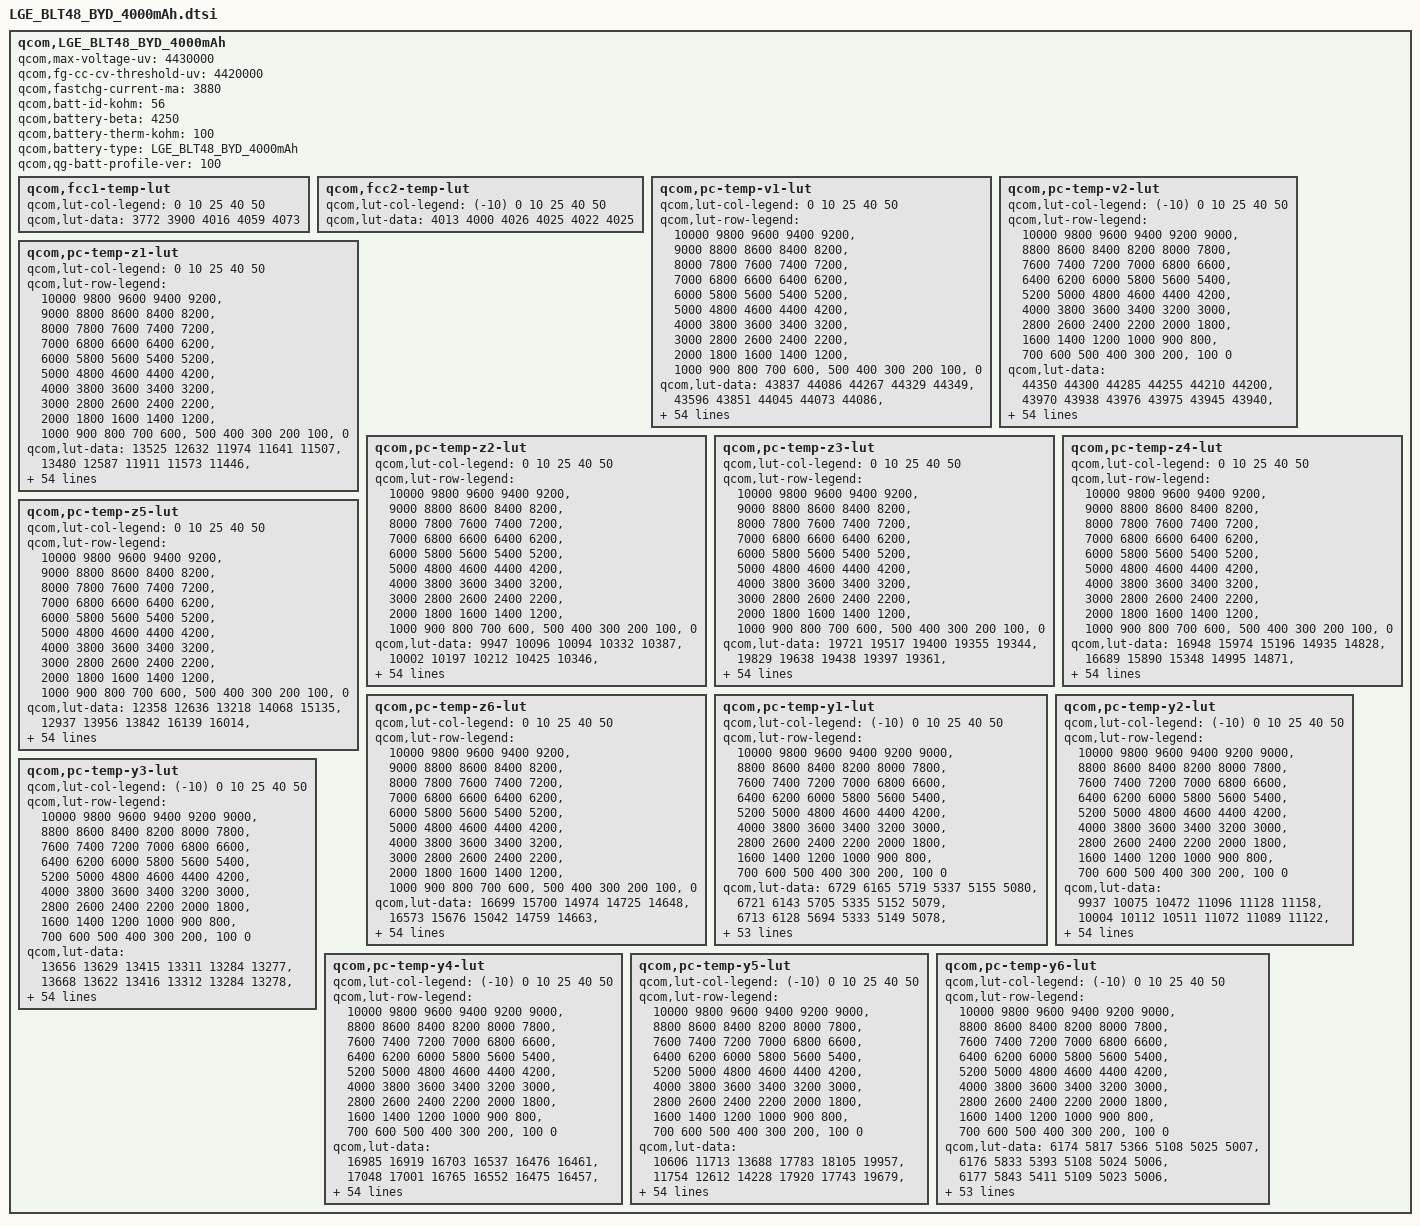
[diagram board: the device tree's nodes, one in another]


qcom,LGE_BLT48_BYD_4000mAh {
    /* 4895688_LGE_BYD_4500mAh_averaged_MasterSlave_Nov20th2020 */
    qcom,max-voltage-uv = <4430000>;
    qcom,fg-cc-cv-threshold-uv = <4420000>;
    qcom,fastchg-current-ma = <3880>;
    qcom,batt-id-kohm = <56>;
    qcom,battery-beta = <4250>;
    qcom,battery-therm-kohm = <100>;
    qcom,battery-type = "LGE_BLT48_BYD_4000mAh";
    qcom,qg-batt-profile-ver = <100>;

	qcom,fcc1-temp-lut {
		qcom,lut-col-legend = <0 10 25 40 50>;
		qcom,lut-data = <3772 3900 4016 4059 4073>;
	};

	qcom,fcc2-temp-lut {
		qcom,lut-col-legend = <(-10) 0 10 25 40 50>;
		qcom,lut-data = <4013 4000 4026 4025 4022 4025>;
	};

	qcom,pc-temp-v1-lut {
		qcom,lut-col-legend = <0 10 25 40 50>;
		qcom,lut-row-legend = <10000 9800 9600 9400 9200>,
			<9000 8800 8600 8400 8200>,
			<8000 7800 7600 7400 7200>,
			<7000 6800 6600 6400 6200>,
			<6000 5800 5600 5400 5200>,
			<5000 4800 4600 4400 4200>,
			<4000 3800 3600 3400 3200>,
			<3000 2800 2600 2400 2200>,
			<2000 1800 1600 1400 1200>,
			<1000 900 800 700 600>,
			<500 400 300 200 100>,
			<0>;
		qcom,lut-data = <43837 44086 44267 44329 44349>,
			<43596 43851 44045 44073 44086>,
			<43358 43622 43817 43855 43863>,
			<43121 43400 43590 43644 43651>,
			<42886 43172 43366 43423 43433>,
			<42653 42933 43137 43199 43213>,
			<42419 42690 42899 42968 42986>,
			<42187 42450 42655 42729 42747>,
			<41960 42212 42411 42486 42503>,
			<41737 41978 42168 42242 42260>,
			<41518 41747 41928 41997 42016>,
			<41305 41521 41694 41758 41778>,
			<41097 41300 41465 41526 41544>,
			<40895 41086 41242 41297 41314>,
			<40694 40876 41025 41074 41089>,
			<40499 40670 40816 40855 40868>,
			<40310 40470 40613 40645 40658>,
			<40125 40285 40417 40443 40456>,
			<39953 40117 40231 40251 40264>,
			<39805 39955 40062 40077 40086>,
			<39673 39792 39882 39906 39914>,
			<39536 39629 39644 39698 39714>,
			<39392 39443 39376 39449 39474>,
			<39245 39183 39173 39227 39250>,
			<39094 38936 39020 39051 39068>,
			<38934 38802 38891 38899 38908>,
			<38788 38713 38779 38769 38771>,
			<38667 38642 38680 38657 38653>,
			<38561 38578 38588 38556 38547>,
			<38483 38521 38499 38460 38449>,
			<38432 38463 38421 38374 38360>,
			<38390 38404 38354 38295 38279>,
			<38352 38350 38296 38222 38203>,
			<38318 38302 38243 38158 38135>,
			<38285 38258 38196 38108 38078>,
			<38251 38219 38150 38059 38022>,
			<38216 38187 38107 38004 37956>,
			<38173 38149 38063 37945 37882>,
			<38112 38085 38001 37875 37802>,
			<38036 37991 37913 37791 37715>,
			<37938 37886 37809 37694 37618>,
			<37808 37762 37690 37581 37502>,
			<37660 37620 37550 37448 37367>,
			<37494 37452 37381 37282 37207>,
			<37380 37290 37222 37128 37058>,
			<37267 37179 37111 37026 36962>,
			<37224 37144 37079 36998 36939>,
			<37185 37123 37063 36983 36920>,
			<37152 37096 37040 36965 36903>,
			<37102 37065 37004 36926 36861>,
			<36933 36880 36809 36699 36614>,
			<36500 36450 36388 36274 36186>,
			<35928 35888 35829 35708 35620>,
			<35159 35122 35063 34937 34850>,
			<33921 33918 33878 33747 33654>,
			<30000 30000 30000 30000 30000>;
	};

	qcom,pc-temp-v2-lut {
		qcom,lut-col-legend = <(-10) 0 10 25 40 50>;
		qcom,lut-row-legend = <10000 9800 9600 9400 9200 9000>,
			<8800 8600 8400 8200 8000 7800>,
			<7600 7400 7200 7000 6800 6600>,
			<6400 6200 6000 5800 5600 5400>,
			<5200 5000 4800 4600 4400 4200>,
			<4000 3800 3600 3400 3200 3000>,
			<2800 2600 2400 2200 2000 1800>,
			<1600 1400 1200 1000 900 800>,
			<700 600 500 400 300 200>,
			<100 0>;
		qcom,lut-data = <44350 44300 44285 44255 44210 44200>,
			<43970 43938 43976 43975 43945 43940>,
			<43631 43613 43692 43713 43693 43691>,
			<43343 43330 43437 43471 43458 43457>,
			<43101 43088 43214 43252 43240 43239>,
			<42862 42848 42987 43029 43018 43017>,
			<42603 42591 42744 42790 42783 42781>,
			<42345 42333 42495 42546 42543 42541>,
			<42122 42091 42247 42305 42303 42302>,
			<41930 41866 41997 42064 42062 42063>,
			<41718 41633 41753 41826 41825 41827>,
			<41430 41359 41518 41591 41589 41592>,
			<41125 41090 41290 41360 41358 41362>,
			<40904 40914 41071 41134 41133 41136>,
			<40743 40803 40860 40915 40914 40914>,
			<40547 40665 40653 40702 40702 40701>,
			<40201 40389 40454 40494 40494 40495>,
			<39811 40040 40252 40292 40294 40295>,
			<39549 39764 40021 40106 40107 40109>,
			<39356 39535 39763 39933 39931 39932>,
			<39174 39323 39519 39738 39738 39739>,
			<38981 39125 39294 39480 39495 39502>,
			<38797 38936 39087 39215 39246 39262>,
			<38635 38727 38904 39011 39045 39062>,
			<38486 38489 38740 38839 38870 38885>,
			<38366 38311 38593 38690 38721 38734>,
			<38276 38216 38465 38562 38595 38607>,
			<38200 38147 38345 38448 38484 38496>,
			<38127 38085 38211 38343 38383 38392>,
			<38060 38031 38070 38247 38288 38294>,
			<37994 37981 37974 38158 38202 38206>,
			<37928 37932 37922 38074 38125 38127>,
			<37862 37885 37879 37997 38051 38052>,
			<37793 37834 37832 37924 37979 37980>,
			<37720 37783 37786 37855 37910 37913>,
			<37644 37728 37739 37787 37830 37829>,
			<37562 37665 37694 37723 37732 37710>,
			<37478 37597 37645 37657 37626 37584>,
			<37399 37525 37582 37584 37532 37482>,
			<37321 37450 37506 37505 37442 37389>,
			<37250 37363 37414 37415 37350 37295>,
			<37185 37249 37294 37310 37254 37200>,
			<37122 37124 37158 37188 37144 37091>,
			<37057 36997 37003 37044 37008 36956>,
			<36984 36899 36857 36900 36875 36824>,
			<36888 36818 36769 36844 36831 36787>,
			<36826 36785 36738 36824 36818 36776>,
			<36757 36745 36703 36805 36803 36762>,
			<36663 36698 36667 36775 36778 36737>,
			<36526 36603 36581 36695 36702 36649>,
			<36284 36372 36341 36441 36448 36362>,
			<35910 35944 35891 35973 35974 35880>,
			<35342 35311 35246 35337 35349 35244>,
			<34522 34392 34320 34449 34495 34375>,
			<33184 32856 32921 33002 33226 33103>,
			<29670 29562 29533 29532 29517 29517>;
	};

	qcom,pc-temp-z1-lut {
		qcom,lut-col-legend = <0 10 25 40 50>;
		qcom,lut-row-legend = <10000 9800 9600 9400 9200>,
			<9000 8800 8600 8400 8200>,
			<8000 7800 7600 7400 7200>,
			<7000 6800 6600 6400 6200>,
			<6000 5800 5600 5400 5200>,
			<5000 4800 4600 4400 4200>,
			<4000 3800 3600 3400 3200>,
			<3000 2800 2600 2400 2200>,
			<2000 1800 1600 1400 1200>,
			<1000 900 800 700 600>,
			<500 400 300 200 100>,
			<0>;
		qcom,lut-data = <13525 12632 11974 11641 11507>,
			<13480 12587 11911 11573 11446>,
			<13446 12561 11883 11549 11427>,
			<13425 12535 11865 11532 11416>,
			<13409 12515 11850 11517 11407>,
			<13394 12502 11838 11505 11400>,
			<13380 12491 11825 11498 11395>,
			<13367 12478 11811 11493 11392>,
			<13352 12463 11803 11490 11390>,
			<13333 12455 11798 11486 11388>,
			<13316 12457 11795 11483 11386>,
			<13305 12461 11794 11481 11385>,
			<13295 12462 11793 11480 11386>,
			<13291 12461 11792 11479 11386>,
			<13303 12461 11793 11479 11386>,
			<13319 12465 11794 11480 11385>,
			<13319 12472 11796 11481 11386>,
			<13300 12474 11799 11483 11387>,
			<13284 12469 11803 11486 11389>,
			<13287 12465 11809 11489 11391>,
			<13299 12472 11814 11492 11395>,
			<13310 12494 11817 11495 11397>,
			<13328 12504 11819 11497 11400>,
			<13345 12501 11823 11499 11402>,
			<13346 12497 11834 11504 11406>,
			<13336 12501 11843 11509 11411>,
			<13328 12511 11848 11515 11415>,
			<13334 12518 11852 11520 11420>,
			<13349 12522 11856 11526 11424>,
			<13362 12527 11862 11531 11428>,
			<13377 12531 11868 11536 11432>,
			<13392 12539 11871 11541 11437>,
			<13398 12547 11875 11546 11441>,
			<13399 12552 11878 11551 11446>,
			<13401 12558 11881 11555 11450>,
			<13407 12565 11885 11560 11454>,
			<13414 12575 11893 11566 11459>,
			<13424 12585 11903 11571 11463>,
			<13441 12594 11909 11577 11467>,
			<13457 12605 11913 11582 11472>,
			<13459 12609 11917 11587 11477>,
			<13453 12606 11921 11591 11481>,
			<13459 12606 11927 11597 11485>,
			<13479 12623 11938 11605 11489>,
			<13490 12632 11949 11614 11495>,
			<13472 12662 11954 11621 11499>,
			<13485 12633 11959 11619 11500>,
			<13487 12654 11966 11622 11501>,
			<13474 12639 11965 11624 11503>,
			<13500 12654 11965 11631 11508>,
			<13559 12675 11977 11637 11517>,
			<13561 12697 11992 11650 11527>,
			<13572 12719 12015 11666 11543>,
			<13603 12774 12062 11689 11566>,
			<13603 12774 12062 11689 11566>,
			<13603 12774 12062 11689 11566>;
	};

	qcom,pc-temp-z2-lut {
		qcom,lut-col-legend = <0 10 25 40 50>;
		qcom,lut-row-legend = <10000 9800 9600 9400 9200>,
			<9000 8800 8600 8400 8200>,
			<8000 7800 7600 7400 7200>,
			<7000 6800 6600 6400 6200>,
			<6000 5800 5600 5400 5200>,
			<5000 4800 4600 4400 4200>,
			<4000 3800 3600 3400 3200>,
			<3000 2800 2600 2400 2200>,
			<2000 1800 1600 1400 1200>,
			<1000 900 800 700 600>,
			<500 400 300 200 100>,
			<0>;
		qcom,lut-data = <9947 10096 10094 10332 10387>,
			<10002 10197 10212 10425 10346>,
			<10044 10199 10340 10465 10368>,
			<10072 10169 10374 10484 10404>,
			<10095 10136 10335 10464 10396>,
			<10104 10102 10295 10408 10334>,
			<10096 10071 10285 10380 10295>,
			<10079 10052 10280 10370 10269>,
			<10062 10039 10279 10365 10247>,
			<10039 10033 10282 10378 10248>,
			<10017 10043 10290 10402 10252>,
			<10000 10063 10474 10400 10257>,
			<9985 10080 10882 10332 10266>,
			<9973 10094 11009 10280 10276>,
			<9962 10108 10961 10285 10286>,
			<9954 10124 10918 10297 10296>,
			<9950 10140 10943 10303 10307>,
			<9949 10154 10999 10307 10317>,
			<9948 10167 10982 10312 10329>,
			<9952 10181 10654 10320 10346>,
			<9964 10199 10373 10332 10368>,
			<9977 10221 10397 10364 10385>,
			<9995 10233 10459 10448 10404>,
			<10016 10238 10471 10518 10414>,
			<10038 10240 10419 10561 10404>,
			<10064 10241 10377 10590 10383>,
			<10084 10242 10388 10568 10368>,
			<10096 10244 10413 10471 10338>,
			<10104 10248 10416 10411 10307>,
			<10111 10252 10393 10393 10275>,
			<10115 10256 10374 10384 10249>,
			<10120 10259 10377 10387 10250>,
			<10124 10264 10386 10399 10267>,
			<10129 10273 10401 10417 10292>,
			<10134 10285 10434 10455 10338>,
			<10141 10295 10462 10502 10394>,
			<10149 10302 10473 10550 10446>,
			<10159 10311 10483 10602 10500>,
			<10175 10327 10495 10630 10533>,
			<10191 10347 10522 10649 10561>,
			<10201 10354 10539 10660 10579>,
			<10208 10351 10534 10645 10556>,
			<10217 10349 10524 10623 10519>,
			<10225 10353 10511 10645 10520>,
			<9633 10430 10519 10620 10517>,
			<9690 10461 10534 10514 10518>,
			<9724 10449 10519 10519 10519>,
			<9704 10453 10509 10536 10510>,
			<9695 10455 10490 10515 10526>,
			<9706 10494 10508 10589 10613>,
			<9680 10482 10553 10528 10431>,
			<9574 10435 10493 10428 10341>,
			<9492 10341 10471 10405 10304>,
			<9367 10169 10443 10336 10263>,
			<9367 10169 10443 10336 10263>,
			<9367 10169 10443 10336 10263>;
	};

	qcom,pc-temp-z3-lut {
		qcom,lut-col-legend = <0 10 25 40 50>;
		qcom,lut-row-legend = <10000 9800 9600 9400 9200>,
			<9000 8800 8600 8400 8200>,
			<8000 7800 7600 7400 7200>,
			<7000 6800 6600 6400 6200>,
			<6000 5800 5600 5400 5200>,
			<5000 4800 4600 4400 4200>,
			<4000 3800 3600 3400 3200>,
			<3000 2800 2600 2400 2200>,
			<2000 1800 1600 1400 1200>,
			<1000 900 800 700 600>,
			<500 400 300 200 100>,
			<0>;
		qcom,lut-data = <19721 19517 19400 19355 19344>,
			<19829 19638 19438 19397 19361>,
			<19892 19678 19491 19408 19375>,
			<19891 19697 19513 19414 19382>,
			<19872 19705 19519 19419 19383>,
			<19852 19709 19521 19423 19381>,
			<19832 19711 19517 19423 19380>,
			<19815 19709 19505 19411 19378>,
			<19812 19699 19494 19400 19375>,
			<19815 19685 19482 19398 19374>,
			<19818 19667 19475 19398 19373>,
			<19819 19647 19483 19395 19370>,
			<19820 19635 19501 19383 19364>,
			<19821 19627 19507 19373 19359>,
			<19828 19621 19496 19371 19357>,
			<19836 19617 19483 19370 19356>,
			<19836 19613 19478 19369 19354>,
			<19823 19608 19475 19369 19348>,
			<19805 19594 19469 19368 19342>,
			<19787 19582 19452 19365 19340>,
			<19768 19583 19439 19363 19338>,
			<19760 19588 19451 19364 19339>,
			<19768 19594 19475 19372 19344>,
			<19779 19606 19480 19380 19351>,
			<19788 19617 19460 19390 19362>,
			<19798 19617 19443 19399 19374>,
			<19805 19609 19453 19404 19380>,
			<19804 19604 19475 19407 19383>,
			<19802 19602 19486 19409 19385>,
			<19798 19601 19491 19405 19379>,
			<19790 19602 19493 19401 19369>,
			<19778 19608 19489 19398 19364>,
			<19768 19612 19479 19395 19361>,
			<19759 19610 19473 19392 19357>,
			<19750 19606 19468 19386 19352>,
			<19744 19601 19464 19381 19347>,
			<19739 19595 19461 19378 19347>,
			<19733 19589 19459 19377 19347>,
			<19725 19584 19456 19376 19347>,
			<19716 19579 19452 19376 19348>,
			<19706 19575 19449 19375 19349>,
			<19694 19571 19447 19372 19351>,
			<19682 19565 19445 19368 19352>,
			<19666 19554 19440 19370 19350>,
			<19301 19519 19425 19366 19346>,
			<19267 19502 19416 19355 19341>,
			<19266 19502 19418 19355 19333>,
			<19266 19483 19408 19347 19333>,
			<19266 19479 19407 19345 19329>,
			<19266 19415 19404 19341 19321>,
			<19266 19477 19399 19350 19344>,
			<19268 19472 19403 19360 19352>,
			<19270 19414 19374 19359 19350>,
			<19276 19340 19363 19365 19347>,
			<19276 19340 19363 19365 19347>,
			<19276 19340 19363 19365 19347>;
	};

	qcom,pc-temp-z4-lut {
		qcom,lut-col-legend = <0 10 25 40 50>;
		qcom,lut-row-legend = <10000 9800 9600 9400 9200>,
			<9000 8800 8600 8400 8200>,
			<8000 7800 7600 7400 7200>,
			<7000 6800 6600 6400 6200>,
			<6000 5800 5600 5400 5200>,
			<5000 4800 4600 4400 4200>,
			<4000 3800 3600 3400 3200>,
			<3000 2800 2600 2400 2200>,
			<2000 1800 1600 1400 1200>,
			<1000 900 800 700 600>,
			<500 400 300 200 100>,
			<0>;
		qcom,lut-data = <16948 15974 15196 14935 14828>,
			<16689 15890 15348 14995 14871>,
			<16444 15739 15210 14948 14854>,
			<16209 15513 15096 14884 14823>,
			<15982 15328 15011 14843 14797>,
			<15792 15205 14941 14808 14771>,
			<15647 15105 14888 14787 14756>,
			<15524 15027 14844 14775 14748>,
			<15413 14961 14820 14765 14743>,
			<15313 14915 14810 14753 14735>,
			<15225 14886 14800 14741 14727>,
			<15149 14865 14768 14736 14720>,
			<15081 14848 14720 14734 14715>,
			<15026 14833 14704 14732 14710>,
			<14973 14823 14703 14725 14703>,
			<14934 14819 14702 14715 14694>,
			<14924 14817 14699 14707 14688>,
			<14924 14813 14695 14699 14685>,
			<14924 14804 14695 14693 14681>,
			<14916 14796 14707 14688 14676>,
			<14897 14793 14727 14684 14670>,
			<14882 14792 14774 14699 14678>,
			<14872 14797 14848 14772 14739>,
			<14864 14892 14891 14813 14782>,
			<14868 15003 14917 14810 14778>,
			<14897 15013 14931 14803 14768>,
			<14930 14998 14909 14791 14756>,
			<14953 14979 14860 14768 14737>,
			<14973 14952 14831 14750 14723>,
			<14980 14921 14812 14739 14717>,
			<14969 14899 14803 14731 14712>,
			<14952 14880 14802 14726 14706>,
			<14937 14868 14801 14722 14700>,
			<14923 14863 14802 14721 14697>,
			<14909 14859 14804 14722 14695>,
			<14895 14855 14806 14723 14694>,
			<14883 14849 14809 14730 14700>,
			<14871 14846 14812 14744 14717>,
			<14861 14847 14813 14748 14723>,
			<14852 14849 14813 14748 14722>,
			<14847 14850 14813 14748 14720>,
			<14842 14833 14799 14741 14713>,
			<14831 14814 14777 14727 14704>,
			<14813 14799 14766 14721 14706>,
			<15068 14760 14741 14711 14700>,
			<15088 14736 14715 14698 14686>,
			<15078 14728 14702 14688 14681>,
			<15074 14729 14691 14675 14663>,
			<15067 14723 14678 14657 14646>,
			<15056 14781 14675 14657 14647>,
			<15059 14722 14697 14671 14652>,
			<15092 14748 14698 14664 14648>,
			<15108 14817 14726 14664 14649>,
			<15134 14906 14735 14656 14652>,
			<15134 14906 14735 14656 14652>,
			<15134 14906 14735 14656 14652>;
	};

	qcom,pc-temp-z5-lut {
		qcom,lut-col-legend = <0 10 25 40 50>;
		qcom,lut-row-legend = <10000 9800 9600 9400 9200>,
			<9000 8800 8600 8400 8200>,
			<8000 7800 7600 7400 7200>,
			<7000 6800 6600 6400 6200>,
			<6000 5800 5600 5400 5200>,
			<5000 4800 4600 4400 4200>,
			<4000 3800 3600 3400 3200>,
			<3000 2800 2600 2400 2200>,
			<2000 1800 1600 1400 1200>,
			<1000 900 800 700 600>,
			<500 400 300 200 100>,
			<0>;
		qcom,lut-data = <12358 12636 13218 14068 15135>,
			<12937 13956 13842 16139 16014>,
			<13374 14674 15550 17009 17224>,
			<13617 15123 16692 17611 18077>,
			<13775 15600 17267 18277 18524>,
			<13931 16212 17739 18892 18836>,
			<14097 16883 18318 19012 18976>,
			<14274 17571 18897 18649 19090>,
			<14521 18309 19057 18348 19257>,
			<14892 18923 18966 18685 19567>,
			<15342 19319 18882 19380 20054>,
			<15816 19653 20554 19439 20198>,
			<16361 20090 24403 18412 19725>,
			<17088 20666 25563 17619 19272>,
			<18661 21341 24590 17851 19668>,
			<20322 22308 23728 18429 20623>,
			<20641 23380 23944 19016 20838>,
			<20336 23610 24485 19710 20135>,
			<20063 22645 24578 20358 19580>,
			<19997 21716 23829 21023 20057>,
			<19906 22897 23188 21652 20951>,
			<20005 26842 27026 21925 21053>,
			<22469 30485 35019 22107 20220>,
			<26568 33856 36243 22081 19236>,
			<30306 36317 26891 20284 18263>,
			<34749 35305 19214 18007 17412>,
			<37489 30313 19482 17923 17627>,
			<37366 26784 20630 18837 19236>,
			<36746 25726 22220 19871 20181>,
			<35964 25092 25188 20832 20180>,
			<34152 25333 27730 21969 20166>,
			<31943 27355 28774 23704 20522>,
			<30492 29517 29498 26069 21843>,
			<29281 31058 30204 27475 22947>,
			<28665 32340 31049 28190 23718>,
			<28736 32615 31542 28567 24204>,
			<28947 32405 31374 28219 24107>,
			<29199 32117 30874 27131 23710>,
			<29643 31874 30120 26108 23373>,
			<30034 31611 28152 24887 22885>,
			<29712 31303 26838 23829 22508>,
			<28342 30932 27064 23251 22912>,
			<27731 30268 27334 22846 23628>,
			<27465 28306 26115 22810 21886>,
			<12689 28075 25125 22036 21044>,
			<11360 26977 25497 20897 20298>,
			<11307 26927 27255 21823 18947>,
			<11285 22559 25022 21274 20969>,
			<11250 22563 26929 23817 24246>,
			<11221 16310 26280 22656 21714>,
			<11236 21703 20690 19662 22908>,
			<11246 18633 19720 20729 24262>,
			<11157 14810 15436 19829 22580>,
			<11056 11897 14347 21075 20435>,
			<11056 11897 14347 21075 20435>,
			<11056 11897 14347 21075 20435>;
	};

	qcom,pc-temp-z6-lut {
		qcom,lut-col-legend = <0 10 25 40 50>;
		qcom,lut-row-legend = <10000 9800 9600 9400 9200>,
			<9000 8800 8600 8400 8200>,
			<8000 7800 7600 7400 7200>,
			<7000 6800 6600 6400 6200>,
			<6000 5800 5600 5400 5200>,
			<5000 4800 4600 4400 4200>,
			<4000 3800 3600 3400 3200>,
			<3000 2800 2600 2400 2200>,
			<2000 1800 1600 1400 1200>,
			<1000 900 800 700 600>,
			<500 400 300 200 100>,
			<0>;
		qcom,lut-data = <16699 15700 14974 14725 14648>,
			<16573 15676 15042 14759 14663>,
			<16443 15613 14994 14739 14658>,
			<16303 15490 14948 14712 14648>,
			<16152 15385 14907 14695 14637>,
			<16023 15315 14869 14681 14625>,
			<15923 15256 14837 14668 14615>,
			<15838 15204 14808 14656 14611>,
			<15767 15157 14789 14646 14607>,
			<15706 15120 14777 14639 14602>,
			<15653 15093 14767 14634 14598>,
			<15607 15072 14757 14628 14593>,
			<15566 15057 14748 14621 14587>,
			<15537 15045 14740 14615 14582>,
			<15518 15036 14733 14610 14578>,
			<15504 15032 14727 14605 14574>,
			<15494 15029 14723 14602 14570>,
			<15488 15024 14720 14598 14565>,
			<15482 15013 14719 14595 14561>,
			<15471 15005 14718 14592 14557>,
			<15456 15006 14718 14589 14554>,
			<15451 15011 14741 14596 14558>,
			<15454 15021 14791 14632 14587>,
			<15461 15071 14809 14656 14611>,
			<15471 15126 14812 14662 14617>,
			<15493 15131 14814 14665 14620>,
			<15514 15124 14810 14663 14619>,
			<15527 15115 14803 14656 14614>,
			<15539 15104 14798 14650 14608>,
			<15542 15094 14796 14644 14603>,
			<15536 15091 14793 14639 14597>,
			<15527 15091 14790 14636 14592>,
			<15520 15090 14787 14634 14588>,
			<15513 15088 14786 14632 14585>,
			<15508 15086 14786 14629 14581>,
			<15504 15084 14786 14627 14578>,
			<15502 15083 14788 14630 14581>,
			<15501 15082 14790 14635 14589>,
			<15502 15084 14791 14638 14592>,
			<15503 15090 14792 14639 14593>,
			<15504 15093 14792 14639 14593>,
			<15506 15089 14788 14635 14591>,
			<15507 15086 14781 14629 14589>,
			<15505 15084 14778 14629 14589>,
			<15457 15067 14766 14625 14586>,
			<15454 15056 14755 14614 14578>,
			<15454 15054 14751 14610 14572>,
			<15455 15048 14743 14600 14564>,
			<15456 15048 14739 14592 14555>,
			<15460 15047 14740 14591 14551>,
			<15480 15065 14751 14604 14568>,
			<15511 15085 14760 14609 14573>,
			<15542 15100 14764 14612 14576>,
			<15591 15125 14773 14617 14580>,
			<15591 15125 14773 14617 14580>,
			<15591 15125 14773 14617 14580>;
	};

	qcom,pc-temp-y1-lut {
		qcom,lut-col-legend = <(-10) 0 10 25 40 50>;
		qcom,lut-row-legend = <10000 9800 9600 9400 9200 9000>,
			<8800 8600 8400 8200 8000 7800>,
			<7600 7400 7200 7000 6800 6600>,
			<6400 6200 6000 5800 5600 5400>,
			<5200 5000 4800 4600 4400 4200>,
			<4000 3800 3600 3400 3200 3000>,
			<2800 2600 2400 2200 2000 1800>,
			<1600 1400 1200 1000 900 800>,
			<700 600 500 400 300 200>,
			<100 0>;
		qcom,lut-data = <6729 6165 5719 5337 5155 5080>,
			<6721 6143 5705 5335 5152 5079>,
			<6713 6128 5694 5333 5149 5078>,
			<6706 6118 5686 5331 5146 5076>,
			<6700 6114 5682 5328 5143 5075>,
			<6699 6114 5680 5326 5141 5073>,
			<6703 6124 5683 5324 5139 5072>,
			<6709 6138 5688 5321 5137 5070>,
			<6712 6139 5690 5321 5134 5069>,
			<6715 6132 5689 5321 5132 5068>,
			<6717 6127 5688 5322 5129 5067>,
			<6722 6131 5688 5320 5128 5067>,
			<6726 6137 5688 5317 5127 5068>,
			<6726 6140 5690 5316 5126 5067>,
			<6721 6142 5693 5315 5126 5066>,
			<6720 6144 5695 5315 5126 5066>,
			<6728 6151 5696 5316 5126 5066>,
			<6738 6158 5697 5318 5125 5067>,
			<6743 6158 5698 5321 5126 5067>,
			<6746 6153 5699 5325 5127 5068>,
			<6748 6150 5701 5328 5129 5069>,
			<6747 6153 5703 5328 5131 5070>,
			<6746 6158 5706 5328 5133 5072>,
			<6746 6159 5710 5330 5135 5074>,
			<6746 6158 5717 5334 5137 5075>,
			<6744 6157 5720 5338 5140 5077>,
			<6736 6155 5720 5342 5143 5079>,
			<6725 6153 5719 5347 5146 5081>,
			<6723 6154 5720 5351 5149 5084>,
			<6725 6161 5721 5357 5153 5086>,
			<6726 6166 5722 5361 5156 5088>,
			<6727 6162 5727 5365 5160 5091>,
			<6729 6156 5732 5368 5163 5094>,
			<6731 6156 5734 5371 5168 5097>,
			<6739 6163 5738 5375 5173 5100>,
			<6743 6166 5739 5378 5177 5102>,
			<6744 6163 5737 5384 5181 5106>,
			<6747 6159 5735 5391 5184 5109>,
			<6749 6160 5735 5395 5187 5112>,
			<6753 6164 5733 5398 5191 5115>,
			<6754 6169 5734 5402 5194 5117>,
			<6763 6180 5741 5413 5196 5119>,
			<6772 6189 5746 5417 5199 5122>,
			<6755 6183 5749 5418 5205 5125>,
			<6759 6187 5761 5426 5214 5129>,
			<6830 6199 5763 5424 5215 5133>,
			<6831 6206 5772 5433 5217 5134>,
			<6840 6210 5778 5435 5220 5134>,
			<6879 6214 5778 5433 5222 5134>,
			<6919 6230 5781 5435 5222 5135>,
			<6976 6261 5799 5444 5223 5139>,
			<7048 6282 5827 5455 5232 5146>,
			<7083 6355 5864 5476 5248 5157>,
			<7088 6389 5891 5497 5268 5173>,
			<7088 6389 5891 5497 5268 5173>,
			<7088 6389 5891 5497 5268 5173>;
	};

	qcom,pc-temp-y2-lut {
		qcom,lut-col-legend = <(-10) 0 10 25 40 50>;
		qcom,lut-row-legend = <10000 9800 9600 9400 9200 9000>,
			<8800 8600 8400 8200 8000 7800>,
			<7600 7400 7200 7000 6800 6600>,
			<6400 6200 6000 5800 5600 5400>,
			<5200 5000 4800 4600 4400 4200>,
			<4000 3800 3600 3400 3200 3000>,
			<2800 2600 2400 2200 2000 1800>,
			<1600 1400 1200 1000 900 800>,
			<700 600 500 400 300 200>,
			<100 0>;
		qcom,lut-data = <9937 10075 10472 11096 11128 11158>,
			<10004 10112 10511 11072 11089 11122>,
			<10072 10171 10571 11047 11050 11080>,
			<10135 10236 10633 11021 11013 11036>,
			<10190 10290 10682 10994 10978 10997>,
			<10229 10316 10701 10967 10948 10969>,
			<10250 10321 10695 10936 10917 10946>,
			<10268 10324 10687 10908 10891 10926>,
			<10324 10347 10689 10895 10883 10912>,
			<10465 10446 10702 10887 10880 10895>,
			<10545 10511 10710 10883 10884 10886>,
			<10532 10512 10703 10881 10898 10888>,
			<10514 10509 10695 10882 10920 10891>,
			<10527 10529 10705 10892 10949 10891>,
			<10600 10631 10759 10923 10989 10888>,
			<10640 10742 10828 10961 11021 10898>,
			<10273 10831 10934 11005 11036 10934>,
			<9763 10910 11032 11057 11051 10987>,
			<9682 10962 11049 11129 11105 11056>,
			<9681 11002 11052 11225 11235 11157>,
			<9679 11019 11056 11265 11297 11218>,
			<9677 10608 11068 11218 11255 11213>,
			<9674 9955 11084 11161 11197 11192>,
			<9672 9765 11104 11158 11176 11182>,
			<9671 9711 11131 11173 11172 11155>,
			<9669 9688 11139 11191 11175 11148>,
			<9668 9683 11060 11219 11188 11179>,
			<9667 9680 10969 11254 11210 11223>,
			<9666 9677 10963 11287 11250 11261>,
			<9665 9673 10975 11322 11326 11302>,
			<9664 9671 10979 11351 11381 11336>,
			<9664 9669 10963 11379 11408 11359>,
			<9664 9667 10928 11398 11431 11383>,
			<9663 9665 10751 11392 11470 11434>,
			<9663 9664 10313 11363 11527 11507>,
			<9662 9663 10011 11329 11547 11527>,
			<9662 9662 9837 11286 11488 11434>,
			<9661 9661 9730 11239 11406 11334>,
			<9661 9661 9701 11200 11353 11319>,
			<9661 9660 9686 11165 11309 11315>,
			<9660 9660 9677 11125 11284 11306>,
			<9660 9659 9672 11077 11273 11268>,
			<9660 9659 9668 11026 11262 11246>,
			<9659 9659 9665 10969 11249 11240>,
			<9658 9658 9663 10892 11145 11203>,
			<9658 9658 9662 10904 11117 11071>,
			<9656 9657 9661 10872 11077 11007>,
			<9655 9657 9660 10857 11089 11038>,
			<9653 9656 9659 10847 11106 11037>,
			<9652 9655 9658 10841 11117 11041>,
			<9650 9653 9657 10778 11094 11013>,
			<9649 9652 9655 10684 11016 10922>,
			<9649 9650 9653 10585 10960 10843>,
			<9648 9649 9651 10473 10901 10778>,
			<9648 9649 9651 10473 10901 10778>,
			<9648 9649 9651 10473 10901 10778>;
	};

	qcom,pc-temp-y3-lut {
		qcom,lut-col-legend = <(-10) 0 10 25 40 50>;
		qcom,lut-row-legend = <10000 9800 9600 9400 9200 9000>,
			<8800 8600 8400 8200 8000 7800>,
			<7600 7400 7200 7000 6800 6600>,
			<6400 6200 6000 5800 5600 5400>,
			<5200 5000 4800 4600 4400 4200>,
			<4000 3800 3600 3400 3200 3000>,
			<2800 2600 2400 2200 2000 1800>,
			<1600 1400 1200 1000 900 800>,
			<700 600 500 400 300 200>,
			<100 0>;
		qcom,lut-data = <13656 13629 13415 13311 13284 13277>,
			<13668 13622 13416 13312 13284 13278>,
			<13674 13615 13417 13313 13284 13279>,
			<13673 13608 13418 13315 13284 13279>,
			<13669 13602 13418 13316 13285 13280>,
			<13663 13596 13419 13317 13286 13280>,
			<13649 13590 13418 13317 13287 13280>,
			<13633 13584 13418 13317 13288 13280>,
			<13630 13580 13417 13317 13289 13281>,
			<13632 13577 13415 13318 13290 13284>,
			<13632 13572 13413 13320 13291 13287>,
			<13579 13524 13414 13320 13291 13288>,
			<13503 13457 13414 13321 13292 13288>,
			<13493 13449 13408 13321 13294 13289>,
			<13504 13469 13383 13322 13297 13289>,
			<13510 13482 13370 13322 13299 13289>,
			<13504 13471 13377 13318 13297 13290>,
			<13495 13450 13385 13314 13295 13291>,
			<13495 13430 13384 13315 13295 13291>,
			<13499 13407 13374 13319 13296 13291>,
			<13504 13395 13364 13321 13296 13291>,
			<13509 13397 13358 13316 13294 13288>,
			<13513 13399 13352 13309 13290 13284>,
			<13512 13398 13347 13306 13287 13282>,
			<13506 13387 13342 13303 13284 13280>,
			<13503 13381 13337 13302 13282 13279>,
			<13519 13382 13332 13301 13282 13279>,
			<13548 13386 13328 13300 13281 13279>,
			<13575 13395 13325 13300 13282 13278>,
			<13606 13424 13323 13300 13282 13277>,
			<13639 13458 13322 13300 13283 13277>,
			<13672 13490 13324 13299 13283 13277>,
			<13706 13525 13326 13297 13283 13277>,
			<13742 13564 13326 13298 13283 13278>,
			<13780 13608 13325 13298 13284 13279>,
			<13818 13655 13326 13299 13284 13279>,
			<13858 13704 13342 13300 13283 13278>,
			<13898 13753 13366 13300 13282 13276>,
			<13938 13800 13389 13301 13281 13276>,
			<13980 13846 13413 13302 13281 13276>,
			<14023 13886 13443 13303 13280 13277>,
			<14067 13917 13479 13305 13281 13278>,
			<14117 13945 13524 13307 13282 13278>,
			<14183 13977 13579 13308 13283 13278>,
			<14268 14029 13647 13310 13283 13276>,
			<14245 14026 13636 13311 13285 13281>,
			<14412 14095 13705 13313 13286 13283>,
			<14667 14169 13782 13318 13290 13286>,
			<15024 14270 13873 13325 13295 13289>,
			<15629 14424 13970 13331 13296 13288>,
			<16674 14763 14076 13330 13294 13285>,
			<18697 15398 14249 13334 13294 13285>,
			<22936 16757 14628 13343 13296 13287>,
			<33535 19732 15346 13358 13302 13291>,
			<33535 19732 15346 13358 13302 13291>,
			<33535 19732 15346 13358 13302 13291>;
	};

	qcom,pc-temp-y4-lut {
		qcom,lut-col-legend = <(-10) 0 10 25 40 50>;
		qcom,lut-row-legend = <10000 9800 9600 9400 9200 9000>,
			<8800 8600 8400 8200 8000 7800>,
			<7600 7400 7200 7000 6800 6600>,
			<6400 6200 6000 5800 5600 5400>,
			<5200 5000 4800 4600 4400 4200>,
			<4000 3800 3600 3400 3200 3000>,
			<2800 2600 2400 2200 2000 1800>,
			<1600 1400 1200 1000 900 800>,
			<700 600 500 400 300 200>,
			<100 0>;
		qcom,lut-data = <16985 16919 16703 16537 16476 16461>,
			<17048 17001 16765 16552 16475 16457>,
			<17124 17090 16833 16561 16473 16454>,
			<17197 17172 16896 16566 16472 16452>,
			<17251 17232 16943 16568 16471 16450>,
			<17272 17255 16960 16569 16470 16450>,
			<17264 17243 16951 16565 16469 16451>,
			<17247 17220 16933 16559 16468 16452>,
			<17229 17199 16917 16558 16468 16452>,
			<17205 17174 16899 16557 16470 16450>,
			<17193 17162 16891 16556 16472 16450>,
			<17233 17214 16891 16559 16476 16452>,
			<17292 17296 16892 16565 16480 16456>,
			<17297 17317 16910 16572 16484 16460>,
			<17268 17320 16974 16583 16486 16466>,
			<17224 17319 17008 16597 16490 16472>,
			<17140 17226 16990 16624 16502 16478>,
			<17035 17067 16956 16654 16521 16486>,
			<16971 16989 16913 16675 16544 16501>,
			<16928 16948 16853 16692 16574 16525>,
			<16886 16911 16798 16697 16587 16536>,
			<16829 16870 16754 16644 16559 16522>,
			<16779 16828 16716 16570 16516 16499>,
			<16760 16769 16689 16539 16491 16480>,
			<16750 16682 16669 16519 16472 16460>,
			<16746 16637 16652 16513 16465 16453>,
			<16746 16644 16639 16513 16467 16454>,
			<16746 16656 16625 16514 16471 16456>,
			<16746 16659 16591 16516 16475 16461>,
			<16744 16660 16535 16521 16482 16468>,
			<16742 16661 16514 16526 16491 16477>,
			<16742 16666 16524 16531 16502 16486>,
			<16741 16673 16542 16535 16512 16495>,
			<16741 16681 16567 16533 16516 16502>,
			<16740 16690 16603 16525 16519 16510>,
			<16739 16699 16633 16519 16519 16511>,
			<16740 16707 16656 16515 16501 16492>,
			<16741 16715 16674 16513 16478 16469>,
			<16745 16717 16687 16514 16469 16461>,
			<16754 16718 16696 16518 16463 16456>,
			<16768 16719 16698 16524 16462 16455>,
			<16792 16709 16692 16535 16467 16458>,
			<16823 16690 16685 16547 16470 16459>,
			<16863 16664 16677 16559 16470 16456>,
			<16873 16659 16661 16554 16461 16445>,
			<16797 16653 16653 16533 16460 16447>,
			<16839 16664 16666 16546 16472 16456>,
			<16917 16691 16679 16564 16484 16473>,
			<17016 16724 16715 16586 16505 16502>,
			<17155 16774 16754 16611 16518 16507>,
			<17382 16863 16759 16603 16492 16468>,
			<17855 17009 16773 16602 16476 16456>,
			<19142 17493 16927 16623 16484 16461>,
			<24829 19764 17551 16669 16512 16484>,
			<24829 19764 17551 16669 16512 16484>,
			<24829 19764 17551 16669 16512 16484>;
	};

	qcom,pc-temp-y5-lut {
		qcom,lut-col-legend = <(-10) 0 10 25 40 50>;
		qcom,lut-row-legend = <10000 9800 9600 9400 9200 9000>,
			<8800 8600 8400 8200 8000 7800>,
			<7600 7400 7200 7000 6800 6600>,
			<6400 6200 6000 5800 5600 5400>,
			<5200 5000 4800 4600 4400 4200>,
			<4000 3800 3600 3400 3200 3000>,
			<2800 2600 2400 2200 2000 1800>,
			<1600 1400 1200 1000 900 800>,
			<700 600 500 400 300 200>,
			<100 0>;
		qcom,lut-data = <10606 11713 13688 17783 18105 19957>,
			<11754 12612 14228 17920 17743 19679>,
			<12925 13527 14787 17946 17390 19339>,
			<14025 14387 15316 17883 17076 18984>,
			<14959 15119 15764 17753 16835 18660>,
			<15630 15651 16081 17577 16698 18412>,
			<15990 15964 16319 17219 16683 17572>,
			<16301 16218 16482 16791 16699 16518>,
			<17225 16659 16477 16585 16628 16733>,
			<19519 17437 16359 16463 16459 18420>,
			<20798 17869 16273 16324 16238 19384>,
			<18592 16384 16292 15994 15845 19005>,
			<15420 14092 16326 15558 15464 18297>,
			<15881 14428 16073 15238 15547 17615>,
			<20317 18438 15139 14971 16105 16851>,
			<22890 21024 14672 14713 16401 16314>,
			<19551 20578 16576 14379 15483 15946>,
			<14904 19879 19181 14111 14284 15685>,
			<14404 19773 19918 14867 14212 15538>,
			<15318 19947 20191 17945 14670 15174>,
			<15829 20199 20464 20147 15415 15180>,
			<15759 20767 20815 21093 17960 17485>,
			<15587 21433 21157 21647 20656 20211>,
			<14984 20809 21411 21518 20676 20560>,
			<13303 16845 21606 20878 19542 20259>,
			<12426 13817 21932 20459 18547 19864>,
			<12426 13068 23056 20297 17798 19213>,
			<12426 12629 24144 20204 17292 18367>,
			<12473 12603 23262 20320 17273 17433>,
			<12680 12810 20082 20750 17378 16368>,
			<12912 13076 18218 21089 17496 15989>,
			<13198 13364 17764 21249 17660 16058>,
			<13474 13690 17367 21438 17926 16208>,
			<13598 14018 16410 22166 18569 16763>,
			<13714 14397 14918 23616 19863 18013>,
			<13755 14676 14392 24128 20857 18763>,
			<13608 14808 14759 23119 21566 19083>,
			<13378 14939 15315 21603 22003 19276>,
			<13214 15199 15881 20264 21441 19361>,
			<13065 15764 16499 18886 19646 19415>,
			<13012 16088 16668 17935 18409 19423>,
			<13081 15701 16248 17321 17721 19315>,
			<13182 15088 15701 16867 17510 19329>,
			<13362 14409 15101 16490 17643 19938>,
			<13700 14212 14862 16893 18537 18063>,
			<14089 13802 14329 18286 18201 18934>,
			<13766 14079 14411 17203 16626 18309>,
			<13529 13866 14389 17009 17101 18211>,
			<13148 14242 14488 17025 17984 18064>,
			<12931 14264 14512 17551 18073 16980>,
			<11863 13423 14581 17861 19631 18599>,
			<10730 12367 14325 18335 21008 20165>,
			<9633 11105 13121 18326 21137 20314>,
			<9091 9854 11637 17872 23437 24537>,
			<9091 9854 11637 17872 23437 24537>,
			<9091 9854 11637 17872 23437 24537>;
	};

	qcom,pc-temp-y6-lut {
		qcom,lut-col-legend = <(-10) 0 10 25 40 50>;
		qcom,lut-row-legend = <10000 9800 9600 9400 9200 9000>,
			<8800 8600 8400 8200 8000 7800>,
			<7600 7400 7200 7000 6800 6600>,
			<6400 6200 6000 5800 5600 5400>,
			<5200 5000 4800 4600 4400 4200>,
			<4000 3800 3600 3400 3200 3000>,
			<2800 2600 2400 2200 2000 1800>,
			<1600 1400 1200 1000 900 800>,
			<700 600 500 400 300 200>,
			<100 0>;
		qcom,lut-data = <6174 5817 5366 5108 5025 5007>,
			<6176 5833 5393 5108 5024 5006>,
			<6177 5843 5411 5109 5023 5006>,
			<6177 5848 5421 5109 5023 5006>,
			<6176 5850 5425 5109 5023 5006>,
			<6174 5850 5426 5108 5023 5006>,
			<6162 5843 5420 5106 5023 5006>,
			<6142 5828 5410 5103 5023 5006>,
			<6133 5816 5400 5102 5024 5007>,
			<6129 5807 5390 5102 5025 5008>,
			<6123 5797 5383 5102 5026 5010>,
			<6096 5779 5381 5102 5027 5011>,
			<6064 5761 5379 5104 5029 5013>,
			<6060 5761 5378 5105 5031 5014>,
			<6067 5782 5378 5108 5033 5016>,
			<6070 5795 5377 5112 5036 5018>,
			<6028 5767 5376 5117 5039 5021>,
			<5967 5717 5373 5123 5043 5023>,
			<5953 5689 5364 5129 5049 5028>,
			<5950 5673 5340 5137 5058 5035>,
			<5947 5661 5319 5140 5062 5038>,
			<5942 5654 5304 5121 5052 5032>,
			<5938 5649 5292 5096 5036 5022>,
			<5939 5638 5286 5085 5027 5015>,
			<5943 5620 5281 5078 5020 5007>,
			<5950 5610 5280 5076 5017 5005>,
			<5969 5624 5280 5077 5018 5005>,
			<5996 5653 5280 5078 5019 5006>,
			<6021 5683 5278 5079 5021 5007>,
			<6046 5715 5273 5083 5023 5009>,
			<6073 5751 5271 5086 5027 5011>,
			<6101 5788 5288 5088 5030 5014>,
			<6131 5828 5316 5090 5034 5017>,
			<6161 5869 5341 5092 5036 5020>,
			<6193 5912 5370 5092 5038 5023>,
			<6225 5955 5403 5093 5039 5024>,
			<6257 6000 5442 5095 5033 5017>,
			<6290 6046 5485 5098 5026 5010>,
			<6326 6088 5533 5102 5024 5009>,
			<6364 6129 5584 5108 5022 5008>,
			<6406 6162 5637 5117 5022 5008>,
			<6452 6186 5690 5129 5024 5010>,
			<6506 6208 5746 5143 5027 5011>,
			<6574 6232 5807 5158 5028 5010>,
			<6659 6277 5871 5171 5027 5006>,
			<6640 6282 5865 5159 5028 5011>,
			<6807 6342 5933 5170 5033 5015>,
			<7063 6413 6005 5188 5040 5022>,
			<7413 6508 6095 5208 5050 5033>,
			<7962 6662 6191 5228 5054 5033>,
			<8869 6995 6290 5235 5046 5020>,
			<10547 7579 6454 5256 5042 5018>,
			<13989 8779 6844 5302 5049 5022>,
			<22558 11547 7612 5366 5064 5034>,
			<22558 11547 7612 5366 5064 5034>,
			<22558 11547 7612 5366 5064 5034>;
	};

};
